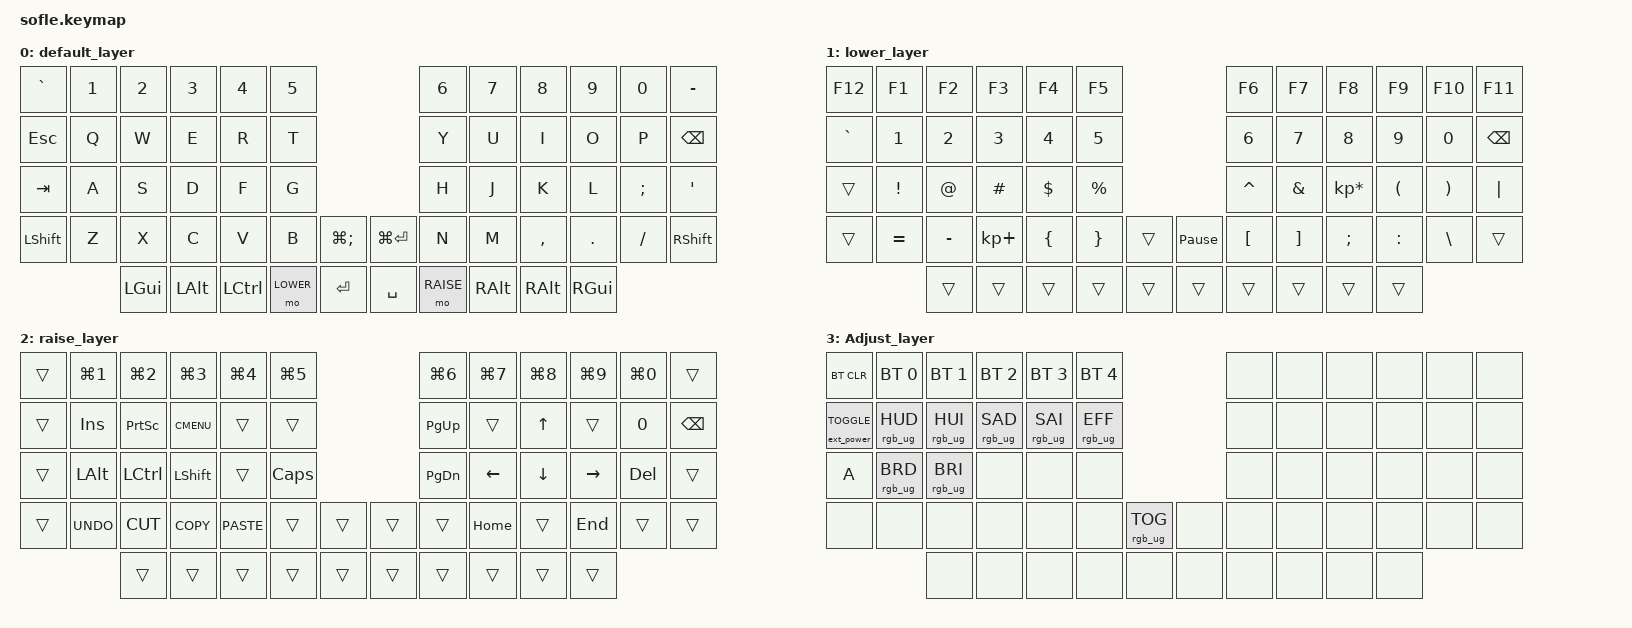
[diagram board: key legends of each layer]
/*
 * Copyright (c) 2020 The ZMK Contributors
 *
 * SPDX-License-Identifier: MIT
 */

#include <behaviors.dtsi>
#include <dt-bindings/zmk/keys.h>
#include <dt-bindings/zmk/bt.h>
#include <dt-bindings/zmk/rgb.h>
#include <dt-bindings/zmk/ext_power.h>

#define BASE 0
#define LOWER 1
#define RAISE 2
#define ADJUST 3

&left_encoder { resolution = <2>; };
&right_encoder { resolution = <4>; };

/ {

   // Activate ADJUST layer by pressing raise and lower
    conditional_layers {
        compatible = "zmk,conditional-layers";
        adjust_layer {
            if-layers = <LOWER RAISE>;
            then-layer = <ADJUST>;
        };
    };

    keymap {
        compatible = "zmk,keymap";

        default_layer {
// --------------------------------------------------------------------------------------------------------------------
// |  `    |  1  |  2  |  3   |  4   |  5   |                           |  6   |  7    |  8    |  9   |   0   |   -   |
// |  ESC  |  Q  |  W  |  E   |  R   |  T   |                           |  Y   |  U    |  I    |  O   |   P   | BKSPC |
// |  TAB  |  A  |  S  |  D   |  F   |  G   |                           |  H   |  J    |  K    |  L   |   ;   |   '   |
// | SHIFT |  Z  |  X  |  C   |  V   |  B   |  MUTE  |  | LGUI+ENTER    |  N   |  M    |  ,    |  .   |   /   | SHIFT |
//               | GUI | ALT  | CTRL | LOWER|  ENTER |  | SPACE         | RAISE| CTRL  | ALT   | GUI  |
            bindings = <
&kp GRAVE &kp N1 &kp N2   &kp N3   &kp N4    &kp N5                              &kp N6 &kp N7    &kp N8    &kp N9   &kp N0   &kp MINUS
&kp ESC   &kp Q  &kp W    &kp E    &kp R     &kp T                               &kp Y  &kp U     &kp I     &kp O    &kp P    &kp BSPC
&kp TAB   &kp A  &kp S    &kp D    &kp F     &kp G                               &kp H  &kp J     &kp K     &kp L    &kp SEMI &kp SQT
&kp LSHFT &kp Z  &kp X    &kp C    &kp V     &kp B      &kp LG(SEMI) &kp LG(RET) &kp N  &kp M     &kp COMMA &kp DOT  &kp FSLH &kp RSHFT
                 &kp LGUI &kp LALT &kp LCTRL &mo LOWER  &kp RET      &kp SPACE   &mo RAISE  &kp RALT &kp RALT  &kp RGUI
            >;

            sensor-bindings = <&inc_dec_kp UP DOWN &inc_dec_kp RIGHT LEFT>;
        };

        lower_layer {
// TODO: Some binds are waiting for shifted keycode support.
// ------------------------------------------------------------------------------------------------------------
// |  F12  |  F1 |  F2 |  F3  |  F4  |  F5  |                   |  F6  |  F7   |  F8   |  F9  |  F10  |  F11  |
// | `     |   1 |   2 |   3  |   4  |   5  |                   |   6  |   7   |   8   |   9  |    0  | BKSPC |
// |       |  !  |  @  |  #   |  $   |  %   |                   |  ^   |  &    |  *    |  (   |   )   |   |   |
// |       |  =  |  -  |  +   |  {   |  }   |        |  | PAUSE |  [   |  ]    |  ;    |  :   |   \   |       |
//               |     |      |      |      |        |  |       |      |       |       |      |
            bindings = <
&kp F12   &kp F1    &kp F2    &kp F3      &kp F4    &kp F5                              &kp F6    &kp F7   &kp F8          &kp F9    &kp F10   &kp F11
&kp GRAVE &kp N1    &kp N2    &kp N3      &kp N4    &kp N5                              &kp N6    &kp N7   &kp N8          &kp N9    &kp N0    &kp BSPC
&trans    &kp EXCL  &kp AT    &kp HASH    &kp DLLR  &kp PRCNT                           &kp CARET &kp AMPS &kp KP_MULTIPLY &kp LPAR  &kp RPAR  &kp PIPE
&trans    &kp EQUAL &kp MINUS &kp KP_PLUS &kp LBRC  &kp RBRC  &trans   &kp PAUSE_BREAK  &kp LBKT  &kp RBKT &kp SEMI        &kp COLON &kp BSLH  &trans
                    &trans    &trans      &trans    &trans    &trans   &trans           &trans    &trans   &trans          &trans
            >;

            sensor-bindings = <&inc_dec_kp UP DOWN &inc_dec_kp LG(PG_DN) LG(PG_UP)>;
        };

        raise_layer {
// ----------------------------------------------------------------------------------------------------------
// |     |LGUI+1|LGUI+2|LGUI+3 |LGUI+4 |LGUI+5|                |LGUI+6|LGUI+7| LGUI+7|LGUI+8|LGUI+9 | LGUI+0|
// |     | INS  | PSCR | GUI   |       |      |                | PGUP |      |   ^   |      |       | BKSPC |
// |     | ALT  | CTRL | SHIFT |       | CAPS |                | PGDN |   <- |   v   |  ->  |  DEL  |       |
// |     | UNDO | CUT  | COPY  | PASTE |      |      |  |      |      | HOME |       | END  |       |       |
//              |      |       |       |      |      |  |      |      |      |       |      |
            bindings = <
&trans     &kp LG(N1)   &kp LG(N2)   &kp LG(N3)   &kp LG(N4)   &kp LG(N5)               &kp LG(N6)&kp LG(N7)&kp LG(N8)&kp LG(N9)&kp LG(N0)   &trans
&trans     &kp INS      &kp PSCRN    &kp K_CMENU  &trans       &trans                   &kp PG_UP &trans    &kp UP    &trans     &kp N0      &kp BSPC
&trans     &kp LALT     &kp LCTRL    &kp LSHFT    &trans       &kp CLCK                 &kp PG_DN &kp LEFT  &kp DOWN  &kp RIGHT  &kp DEL     &trans
&trans     &kp K_UNDO   &kp K_CUT    &kp K_COPY   &kp K_PASTE  &trans  &trans   &trans  &trans    &kp HOME  &trans    &kp END    &trans      &trans
                        &trans       &trans       &trans       &trans  &trans   &trans  &trans    &trans    &trans    &trans
            >;

            sensor-bindings = <&inc_dec_kp UP DOWN &inc_dec_kp RIGHT LEFT>;
        };

// --------------------------------------------------------------------------------------------------------------
// |BTCLR | BT1   | BT2   |  BT3  |  BT4  |  BT5  |                |      |      |       |      |       |       |
// |EXTPWR|RGB_HUD|RGB_HUI|RGB_SAD|RGB_SAI|RGB_EFF|                |      |      |       |      |       |       |
// |      |RGB_BRD|RGB_BRI|       |       |       |                |      |      |       |      |       |       |
// |      |       |       |       |       |       |RGB_TOG| |      |      |      |       |      |       |       |
//                |       |       |       |       |       | |      |      |      |       |      |

        Adjust_layer {
        bindings = <
&bt BT_CLR                      &bt BT_SEL 0    &bt BT_SEL 1    &bt BT_SEL 2    &bt BT_SEL 3    &bt BT_SEL 4                                    &none &none &none &none &none &none
&ext_power EXT_POWER_TOGGLE_CMD &rgb_ug RGB_HUD &rgb_ug RGB_HUI &rgb_ug RGB_SAD &rgb_ug RGB_SAI &rgb_ug RGB_EFF                                 &none &none &none &none &none &none
&kp A                           &rgb_ug RGB_BRD &rgb_ug RGB_BRI &none           &none           &none                                           &none &none &none &none &none &none
&none                           &none           &none           &none           &none           &none               &rgb_ug RGB_TOG  &none      &none &none &none &none &none &none
                                                &none           &none           &none           &none               &none            &none      &none &none &none &none
        >;
        };

    };
};
